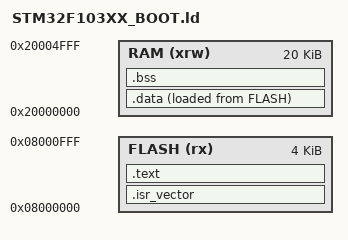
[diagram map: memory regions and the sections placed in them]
ENTRY(Reset_Handler)

MEMORY
{
  RAM (xrw)  : ORIGIN = 0x20000000, LENGTH = 20K
  FLASH (rx) : ORIGIN = 0x08000000, LENGTH = 4K
}

_estack = ORIGIN(RAM) + LENGTH(RAM);

SECTIONS
{
  .isr_vector :
  {
    KEEP(*(.isr_vector))
  } >FLASH

  .text :
  {
    *(.text .text.*)
    *(.rodata .rodata.*)
    . = ALIGN(4);
    _etext = .;
  } >FLASH

  _sidata = LOADADDR(.data);

  .data : ALIGN(4)
  {
    _sdata = .;
    *(.data .data.*)
    . = ALIGN(4);
    _edata = .;
  } >RAM AT> FLASH

  .bss (NOLOAD) : ALIGN(4)
  {
    _sbss = .;
    *(.bss .bss.*)
    *(COMMON)
    . = ALIGN(4);
    _ebss = .;
  } >RAM
}
